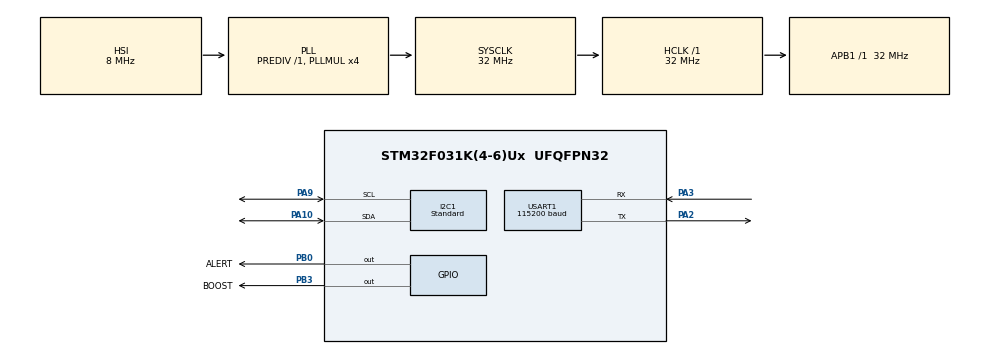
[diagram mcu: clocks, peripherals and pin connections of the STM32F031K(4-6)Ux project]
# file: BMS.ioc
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I2C1.I2C_Fall_Time=5
I2C1.I2C_Rise_Time=5
I2C1.I2C_Speed_Mode=I2C_Standard
I2C1.Speed=100
I2C1.Timing=0x20202B3B
Mcu.Family=STM32F0
Mcu.Name=STM32F031K(4-6)Ux
Mcu.Package=UFQFPN32
NVIC.USART1_IRQn=true\:0\:0\:false\:false\:true\:true\:true\:true
PA10.Mode=I2C
PA10.Signal=I2C1_SDA
PA13.Mode=Serial_Wire
PA13.Signal=SYS_SWDIO
PA14.Mode=Serial_Wire
PA14.Signal=SYS_SWCLK
PA2.Mode=Asynchronous
PA2.Signal=USART1_TX
PA3.Mode=Asynchronous
PA3.Signal=USART1_RX
PA9.Mode=I2C
PA9.Signal=I2C1_SCL
PB0.GPIO_Label=ALERT
PB0.GPIO_Speed=GPIO_SPEED_FREQ_MEDIUM
PB0.PinState=GPIO_PIN_SET
PB0.Signal=GPIO_Output
PB3.GPIO_Label=BOOST
PB3.GPIO_Speed=GPIO_SPEED_FREQ_HIGH
PB3.Signal=GPIO_Output
ProjectManager.HeapSize=0x200
ProjectManager.StackSize=0x400
ProjectManager.TargetToolchain=STM32CubeIDE
RCC.AHBFreq_Value=32000000
RCC.APB1Freq_Value=32000000
RCC.APB1TimFreq_Value=32000000
RCC.HCLKFreq_Value=32000000
RCC.I2c1ClockSelection=RCC_I2C1CLKSOURCE_SYSCLK
RCC.PLLMUL=RCC_PLL_MUL8
RCC.SYSCLKFreq_VALUE=32000000
RCC.SYSCLKSource=RCC_SYSCLKSOURCE_PLLCLK
USART1.BaudRate=115200
USART1.VirtualMode-Asynchronous=VM_ASYNC
board=custom

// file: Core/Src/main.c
/* USER CODE BEGIN Header */
/**
 ******************************************************************************
 * @file           : main.c
 * @brief          : Main program body
 ******************************************************************************
 * @attention
 *
 * Copyright (c) 2024 STMicroelectronics.
 * All rights reserved.
 *
 * This software is licensed under terms that can be found in the LICENSE file
 * in the root directory of this software component.
 * If no LICENSE file comes with this software, it is provided AS-IS.
 *
 ******************************************************************************
 */
/* USER CODE END Header */
#include "main.h"
#include "gpio.h"
#include "i2c.h"
#include "usart.h"

/* USER CODE BEGIN Includes */
#include "utils/bms.h"

/* USER CODE END Includes */

void SystemClock_Config(void);

int main(void) {

  /* MCU Configuration--------------------------------------------------------*/

  /* Reset of all peripherals, Initializes the Flash interface and the Systick.
   */
  HAL_Init();

  /* Configure the system clock */
  SystemClock_Config();

  /* Initialize all configured peripherals */
  MX_GPIO_Init();
  MX_I2C1_Init();
  MX_USART1_UART_Init();
  /* USER CODE BEGIN 2 */
  bms_init();
  /* USER CODE END 2 */

  /* Infinite loop */
  /* USER CODE BEGIN WHILE */
  bms();

  // it shuldn't be in this loop
  while (1) {
    /* USER CODE END WHILE */
    Error_Handler();
  }
}

void SystemClock_Config(void) {
  RCC_OscInitTypeDef RCC_OscInitStruct = {0};
  RCC_ClkInitTypeDef RCC_ClkInitStruct = {0};
  RCC_PeriphCLKInitTypeDef PeriphClkInit = {0};

  /** Initializes the RCC Oscillators according to the specified parameters
   * in the RCC_OscInitTypeDef structure.
   */
  RCC_OscInitStruct.OscillatorType = RCC_OSCILLATORTYPE_HSI;
  RCC_OscInitStruct.HSIState = RCC_HSI_ON;
  RCC_OscInitStruct.HSICalibrationValue = RCC_HSICALIBRATION_DEFAULT;
  RCC_OscInitStruct.PLL.PLLState = RCC_PLL_ON;
  RCC_OscInitStruct.PLL.PLLSource = RCC_PLLSOURCE_HSI;
  RCC_OscInitStruct.PLL.PLLMUL = RCC_PLL_MUL4;
  RCC_OscInitStruct.PLL.PREDIV = RCC_PREDIV_DIV1;
  if (HAL_RCC_OscConfig(&RCC_OscInitStruct) != HAL_OK) {
    Error_Handler();
  }

  /** Initializes the CPU, AHB and APB buses clocks
   */
  RCC_ClkInitStruct.ClockType =
      RCC_CLOCKTYPE_HCLK | RCC_CLOCKTYPE_SYSCLK | RCC_CLOCKTYPE_PCLK1;
  RCC_ClkInitStruct.SYSCLKSource = RCC_SYSCLKSOURCE_PLLCLK;
  RCC_ClkInitStruct.AHBCLKDivider = RCC_SYSCLK_DIV1;
  RCC_ClkInitStruct.APB1CLKDivider = RCC_HCLK_DIV1;

  if (HAL_RCC_ClockConfig(&RCC_ClkInitStruct, FLASH_LATENCY_0) != HAL_OK) {
    Error_Handler();
  }
  PeriphClkInit.PeriphClockSelection =
      RCC_PERIPHCLK_USART1 | RCC_PERIPHCLK_I2C1;
  PeriphClkInit.Usart1ClockSelection = RCC_USART1CLKSOURCE_PCLK1;
  PeriphClkInit.I2c1ClockSelection = RCC_I2C1CLKSOURCE_SYSCLK;
  if (HAL_RCCEx_PeriphCLKConfig(&PeriphClkInit) != HAL_OK) {
    Error_Handler();
  }
}

void Error_Handler(void) {
  __disable_irq();
  while (1) {
  }
}

#ifdef USE_FULL_ASSERT
/**
 * @brief  Reports the name of the source file and the source line number
 *         where the assert_param error has occurred.
 * @param  file: pointer to the source file name
 * @param  line: assert_param error line source number
 * @retval None
 */
void assert_failed(uint8_t *file, uint32_t line) {
  /* USER CODE BEGIN 6 */
  /* User can add his own implementation to report the file name and line
     number, ex: printf("Wrong parameters value: file %s on line %d\r\n", file,
     line) */
  /* USER CODE END 6 */
}
#endif /* USE_FULL_ASSERT */
